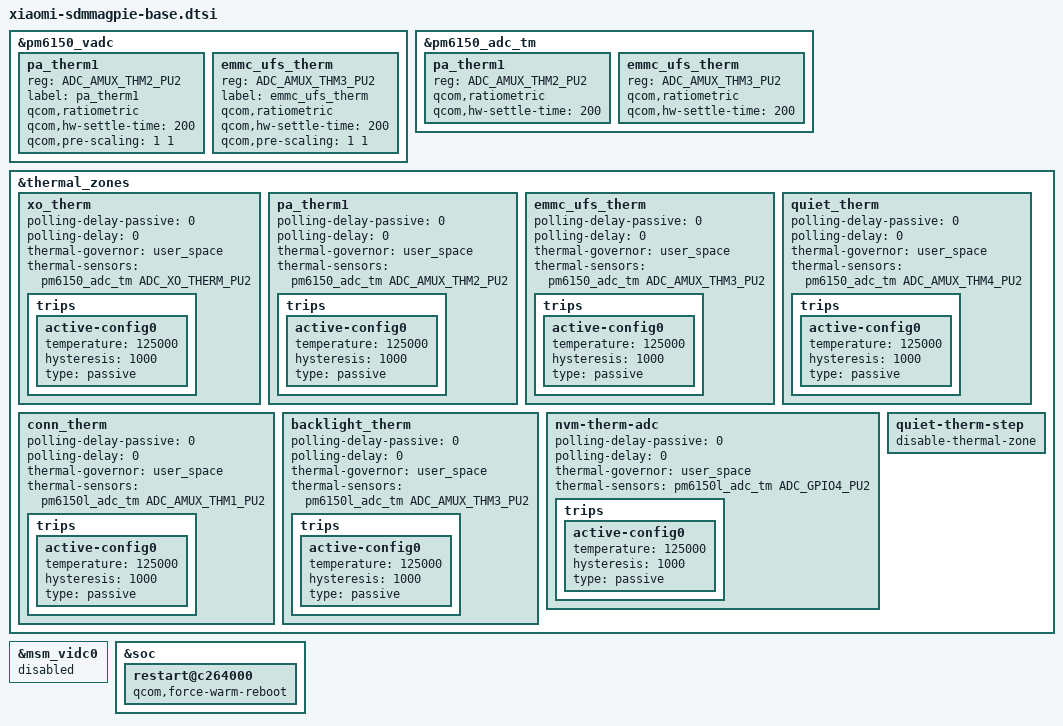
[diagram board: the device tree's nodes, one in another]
/* Copyright (c) 2018, The Linux Foundation. All rights reserved.
 * Copyright (C) 2020 The LineageOS Project
 *
 * This program is free software; you can redistribute it and/or modify
 * it under the terms of the GNU General Public License version 2 and
 * only version 2 as published by the Free Software Foundation.
 *
 * This program is distributed in the hope that it will be useful,
 * but WITHOUT ANY WARRANTY; without even the implied warranty of
 * MERCHANTABILITY or FITNESS FOR A PARTICULAR PURPOSE.  See the
 * GNU General Public License for more details.
 */

#include "../qcom-base/sdmmagpie.dtsi"
#include "xiaomi-sdmmagpie-pmic.dtsi"

&pm6150_vadc {
    /delete-node/ rf_pa0_therm;
    /delete-node/ rf_pa1_therm;

    pa_therm1 {
        reg = <ADC_AMUX_THM2_PU2>;
        label = "pa_therm1";
        qcom,ratiometric;
        qcom,hw-settle-time = <200>;
        qcom,pre-scaling = <1 1>;
    };

    emmc_ufs_therm {
        reg = <ADC_AMUX_THM3_PU2>;
        label = "emmc_ufs_therm";
        qcom,ratiometric;
        qcom,hw-settle-time = <200>;
        qcom,pre-scaling = <1 1>;
    };
};

&pm6150_adc_tm {
    /delete-node/ rf_pa0_therm;
    /delete-node/ rf_pa1_therm;

    pa_therm1 {
        reg = <ADC_AMUX_THM2_PU2>;
        qcom,ratiometric;
        qcom,hw-settle-time = <200>;
    };

    emmc_ufs_therm {
        reg = <ADC_AMUX_THM3_PU2>;
        qcom,ratiometric;
        qcom,hw-settle-time = <200>;
    };
};

&thermal_zones {
    xo_therm {
        polling-delay-passive = <0>;
        polling-delay = <0>;
        thermal-governor = "user_space";
        thermal-sensors = <&pm6150_adc_tm ADC_XO_THERM_PU2>;
        trips {
            active-config0 {
                temperature = <125000>;
                hysteresis = <1000>;
                type = "passive";
            };
        };
    };

    pa_therm1 {
        polling-delay-passive = <0>;
        polling-delay = <0>;
        thermal-governor = "user_space";
        thermal-sensors = <&pm6150_adc_tm ADC_AMUX_THM2_PU2>;
        trips {
            active-config0 {
                temperature = <125000>;
                hysteresis = <1000>;
                type = "passive";
            };
        };
    };

    emmc_ufs_therm {
        polling-delay-passive = <0>;
        polling-delay = <0>;
        thermal-governor = "user_space";
        thermal-sensors = <&pm6150_adc_tm ADC_AMUX_THM3_PU2>;
        trips {
            active-config0 {
                temperature = <125000>;
                hysteresis = <1000>;
                type = "passive";
            };
        };
    };

    quiet_therm {
        polling-delay-passive = <0>;
        polling-delay = <0>;
        thermal-governor = "user_space";
        thermal-sensors = <&pm6150_adc_tm ADC_AMUX_THM4_PU2>;
        trips {
            active-config0 {
                temperature = <125000>;
                hysteresis = <1000>;
                type = "passive";
            };
        };
    };

    conn_therm {
        polling-delay-passive = <0>;
        polling-delay = <0>;
        thermal-governor = "user_space";
        thermal-sensors = <&pm6150l_adc_tm ADC_AMUX_THM1_PU2>;
        trips {
            active-config0 {
                temperature = <125000>;
                hysteresis = <1000>;
                type = "passive";
            };
        };
    };

    backlight_therm {
        polling-delay-passive = <0>;
        polling-delay = <0>;
        thermal-governor = "user_space";
        thermal-sensors = <&pm6150l_adc_tm ADC_AMUX_THM3_PU2>;
        trips {
            active-config0 {
                temperature = <125000>;
                hysteresis = <1000>;
                type = "passive";
            };
        };
    };

    nvm-therm-adc {
        polling-delay-passive = <0>;
        polling-delay = <0>;
        thermal-governor = "user_space";
        thermal-sensors = <&pm6150l_adc_tm ADC_GPIO4_PU2>;
        trips {
            active-config0 {
                temperature = <125000>;
                hysteresis = <1000>;
                type = "passive";
            };
        };
    };

    quiet-therm-step {
        disable-thermal-zone;
    };
};

&msm_vidc0 {
    status = "disabled";
};

&soc {
    restart@c264000 {
        qcom,force-warm-reboot;
    };
};
